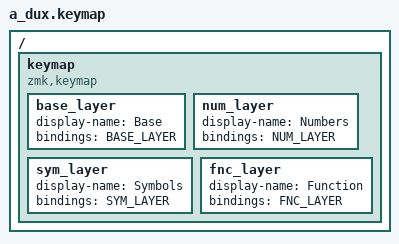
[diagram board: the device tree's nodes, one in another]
/*
 * A_dux Keymap - Using Generic 3x5 Layout
 * 
 * This keymap automatically uses the shared generic_3x5_layers.dtsi
 * Edit config/generic_3x5.keymap with keymap-editor to update all boards
 * add #include <dt-bindings/zmk/bt.h> if Bluetooth keyboard
 */

#include <behaviors.dtsi>
#include <dt-bindings/zmk/keys.h>
#include <dt-bindings/zmk/bt.h>
#include <dt-bindings/zmk/outputs.h>
#include "generic_3x5_behaviors.dtsi"
#include "generic_3x5_layers.dtsi"

/ {
    keymap {
        compatible = "zmk,keymap";

        base_layer {
            display-name = "Base";
            bindings = <
                BASE_LAYER
            >;
        };

        num_layer {
            display-name = "Numbers";
            bindings = <
                NUM_LAYER
            >;
        };

        sym_layer {
            display-name = "Symbols";
            bindings = <
                SYM_LAYER
            >;
        };

        fnc_layer {
            display-name = "Function";
            bindings = <
                FNC_LAYER
            >;
        };
    };
};
